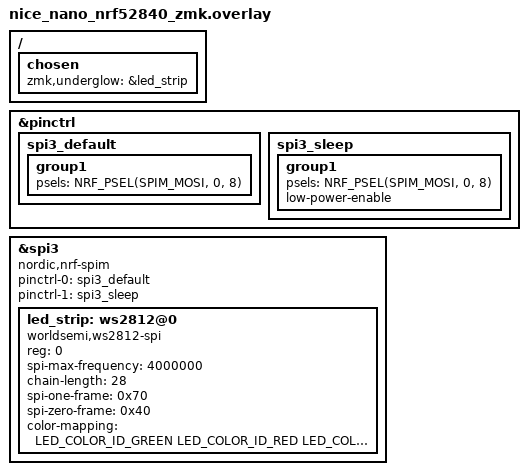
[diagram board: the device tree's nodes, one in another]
/*
 * RGB underglow via SPIM3 MOSI on D0 (P0.08) — bodged from D16 (P0.10) NFC pin.
 * Per ZMK docs: RGB underglow must be configured against a board, not a shield,
 * because the LED-strip driver depends on hardware-specific interfaces (SPI/I2S)
 * which shields cannot control. The shield-dtsi placement also confused Zephyr's
 * DT_HAS_WORLDSEMI_WS2812_SPI_ENABLED detection — moving to boards/<board>.overlay
 * resolves it.
 */

#include <dt-bindings/led/led.h>

&pinctrl {
    spi3_default: spi3_default {
        group1 {
            psels = <NRF_PSEL(SPIM_MOSI, 0, 8)>;
        };
    };

    spi3_sleep: spi3_sleep {
        group1 {
            psels = <NRF_PSEL(SPIM_MOSI, 0, 8)>;
            low-power-enable;
        };
    };
};

&spi3 {
    compatible = "nordic,nrf-spim";
    status = "okay";

    pinctrl-0 = <&spi3_default>;
    pinctrl-1 = <&spi3_sleep>;
    pinctrl-names = "default", "sleep";

    led_strip: ws2812@0 {
        compatible = "worldsemi,ws2812-spi";
        status = "okay";

        /* SPI */
        reg = <0>;
        spi-max-frequency = <4000000>;

        /* WS2812 */
        chain-length = <28>;
        spi-one-frame = <0x70>;
        spi-zero-frame = <0x40>;

        color-mapping = <LED_COLOR_ID_GREEN LED_COLOR_ID_RED LED_COLOR_ID_BLUE>;
    };
};

/ {
    chosen {
        zmk,underglow = &led_strip;
    };
};
